# MIMXRT1021 register map
Vendor: nxp.com; File version: 1.0
CPU: CM7 r0p1, little endian, MPU, FPU, VTOR, 4 interrupt priority bits
Registers are 32-bit, read-write, reset 0x0 unless marked. A register's access mark holds for its fields unless they carry their own. Offsets are from the block's base; [hi:lo] are bit positions.

## IOMUXC (part 1 of 3)
Base 0x401F8000; register names take the prefix IOMUXC_
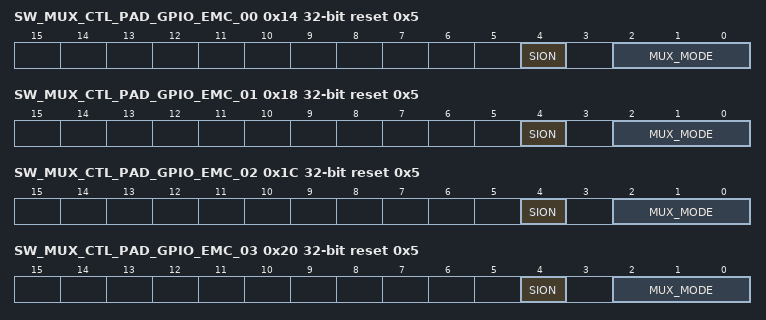
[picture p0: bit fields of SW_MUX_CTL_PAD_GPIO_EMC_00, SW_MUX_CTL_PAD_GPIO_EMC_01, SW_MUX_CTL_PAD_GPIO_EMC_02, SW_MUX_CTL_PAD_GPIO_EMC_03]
0x14 SW_MUX_CTL_PAD_GPIO_EMC_00 reset 0x5 — SW_MUX_CTL_PAD_GPIO_EMC_00 SW MUX Control Register
  [4] SION — Software Input On Field.
    0=DISABLED (Input Path is determined by functionality); 1=ENABLED (Force input path of pad GPIO_EMC_00)
  [2:0] MUX_MODE — MUX Mode Select Field.
    0=ALT0 (Select mux mode: ALT0 mux port: SEMC_DATA00 of instance: semc); 1=ALT1 (Select mux mode: ALT1 mux port: QTIMER2_TIMER0 of instance: qtimer2); 2=ALT2 (Select mux mode: ALT2 mux port: LPUART4_CTS_B of instance: lpuart4); 3=ALT3 (Select mux mode: ALT3 mux port: SPDIF_SR_CLK of instance: spdif); 4=ALT4 (Select mux mode: ALT4 mux port: LPSPI2_SCK of instance: lpspi2); 5=ALT5 (Select mux mode: ALT5 mux port: GPIO2_IO00 of instance: gpio2); 6=ALT6 (Select mux mode: ALT6 mux port: FLEXCAN1_TX of instance: flexcan1); 7=ALT7 (Select mux mode: ALT7 mux port: PIT_TRIGGER02 of instance: pit)
0x18 SW_MUX_CTL_PAD_GPIO_EMC_01 reset 0x5 — SW_MUX_CTL_PAD_GPIO_EMC_01 SW MUX Control Register
  [4] SION — Software Input On Field.
    0=DISABLED (Input Path is determined by functionality); 1=ENABLED (Force input path of pad GPIO_EMC_01)
  [2:0] MUX_MODE — MUX Mode Select Field.
    0=ALT0 (Select mux mode: ALT0 mux port: SEMC_DATA01 of instance: semc); 1=ALT1 (Select mux mode: ALT1 mux port: QTIMER2_TIMER1 of instance: qtimer2); 2=ALT2 (Select mux mode: ALT2 mux port: LPUART4_RTS_B of instance: lpuart4); 3=ALT3 (Select mux mode: ALT3 mux port: SPDIF_OUT of instance: spdif); 4=ALT4 (Select mux mode: ALT4 mux port: LPSPI2_PCS0 of instance: lpspi2); 5=ALT5 (Select mux mode: ALT5 mux port: GPIO2_IO01 of instance: gpio2); 6=ALT6 (Select mux mode: ALT6 mux port: FLEXCAN1_RX of instance: flexcan1); 7=ALT7 (Select mux mode: ALT7 mux port: PIT_TRIGGER03 of instance: pit)
0x1C SW_MUX_CTL_PAD_GPIO_EMC_02 reset 0x5 — SW_MUX_CTL_PAD_GPIO_EMC_02 SW MUX Control Register
  [4] SION — Software Input On Field.
    0=DISABLED (Input Path is determined by functionality); 1=ENABLED (Force input path of pad GPIO_EMC_02)
  [2:0] MUX_MODE — MUX Mode Select Field.
    0=ALT0 (Select mux mode: ALT0 mux port: SEMC_DATA02 of instance: semc); 1=ALT1 (Select mux mode: ALT1 mux port: QTIMER2_TIMER2 of instance: qtimer2); 2=ALT2 (Select mux mode: ALT2 mux port: LPUART4_TX of instance: lpuart4); 3=ALT3 (Select mux mode: ALT3 mux port: SPDIF_LOCK of instance: spdif); 4=ALT4 (Select mux mode: ALT4 mux port: LPSPI2_SDO of instance: lpspi2); 5=ALT5 (Select mux mode: ALT5 mux port: GPIO2_IO02 of instance: gpio2); 6=ALT6 (Select mux mode: ALT6 mux port: LPI2C1_SCL of instance: lpi2c1)
0x20 SW_MUX_CTL_PAD_GPIO_EMC_03 reset 0x5 — SW_MUX_CTL_PAD_GPIO_EMC_03 SW MUX Control Register
  [4] SION — Software Input On Field.
    0=DISABLED (Input Path is determined by functionality); 1=ENABLED (Force input path of pad GPIO_EMC_03)
  [2:0] MUX_MODE — MUX Mode Select Field.
    0=ALT0 (Select mux mode: ALT0 mux port: SEMC_DATA03 of instance: semc); 1=ALT1 (Select mux mode: ALT1 mux port: QTIMER2_TIMER3 of instance: qtimer2); 2=ALT2 (Select mux mode: ALT2 mux port: LPUART4_RX of instance: lpuart4); 3=ALT3 (Select mux mode: ALT3 mux port: SPDIF_EXT_CLK of instance: spdif); 4=ALT4 (Select mux mode: ALT4 mux port: LPSPI2_SDI of instance: lpspi2); 5=ALT5 (Select mux mode: ALT5 mux port: GPIO2_IO03 of instance: gpio2); 6=ALT6 (Select mux mode: ALT6 mux port: LPI2C1_SDA of instance: lpi2c1)
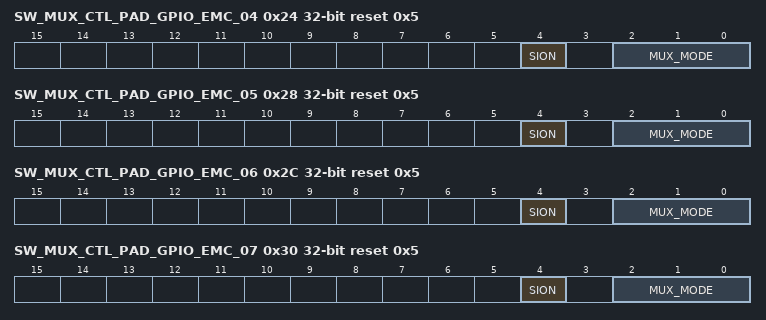
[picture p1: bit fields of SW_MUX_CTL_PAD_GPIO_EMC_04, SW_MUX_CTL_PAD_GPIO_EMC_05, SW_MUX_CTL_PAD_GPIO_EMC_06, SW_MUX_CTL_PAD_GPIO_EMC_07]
0x24 SW_MUX_CTL_PAD_GPIO_EMC_04 reset 0x5 — SW_MUX_CTL_PAD_GPIO_EMC_04 SW MUX Control Register
  [4] SION — Software Input On Field.
    0=DISABLED (Input Path is determined by functionality); 1=ENABLED (Force input path of pad GPIO_EMC_04)
  [2:0] MUX_MODE — MUX Mode Select Field.
    0=ALT0 (Select mux mode: ALT0 mux port: SEMC_DATA04 of instance: semc); 1=ALT1 (Select mux mode: ALT1 mux port: XBAR1_INOUT04 of instance: xbar1); 2=ALT2 (Select mux mode: ALT2 mux port: SPDIF_OUT of instance: spdif); 3=ALT3 (Select mux mode: ALT3 mux port: SAI2_TX_BCLK of instance: sai2); 4=ALT4 (Select mux mode: ALT4 mux port: FLEXIO1_FLEXIO16 of instance: flexio1); 5=ALT5 (Select mux mode: ALT5 mux port: GPIO2_IO04 of instance: gpio2)
0x28 SW_MUX_CTL_PAD_GPIO_EMC_05 reset 0x5 — SW_MUX_CTL_PAD_GPIO_EMC_05 SW MUX Control Register
  [4] SION — Software Input On Field.
    0=DISABLED (Input Path is determined by functionality); 1=ENABLED (Force input path of pad GPIO_EMC_05)
  [2:0] MUX_MODE — MUX Mode Select Field.
    0=ALT0 (Select mux mode: ALT0 mux port: SEMC_DATA05 of instance: semc); 1=ALT1 (Select mux mode: ALT1 mux port: XBAR1_INOUT05 of instance: xbar1); 2=ALT2 (Select mux mode: ALT2 mux port: SPDIF_IN of instance: spdif); 3=ALT3 (Select mux mode: ALT3 mux port: SAI2_TX_SYNC of instance: sai2); 4=ALT4 (Select mux mode: ALT4 mux port: FLEXIO1_FLEXIO17 of instance: flexio1); 5=ALT5 (Select mux mode: ALT5 mux port: GPIO2_IO05 of instance: gpio2)
0x2C SW_MUX_CTL_PAD_GPIO_EMC_06 reset 0x5 — SW_MUX_CTL_PAD_GPIO_EMC_06 SW MUX Control Register
  [4] SION — Software Input On Field.
    0=DISABLED (Input Path is determined by functionality); 1=ENABLED (Force input path of pad GPIO_EMC_06)
  [2:0] MUX_MODE — MUX Mode Select Field.
    0=ALT0 (Select mux mode: ALT0 mux port: SEMC_DATA06 of instance: semc); 1=ALT1 (Select mux mode: ALT1 mux port: XBAR1_INOUT06 of instance: xbar1); 2=ALT2 (Select mux mode: ALT2 mux port: LPUART3_TX of instance: lpuart3); 3=ALT3 (Select mux mode: ALT3 mux port: SAI2_TX_DATA of instance: sai2); 4=ALT4 (Select mux mode: ALT4 mux port: FLEXIO1_FLEXIO18 of instance: flexio1); 5=ALT5 (Select mux mode: ALT5 mux port: GPIO2_IO06 of instance: gpio2)
0x30 SW_MUX_CTL_PAD_GPIO_EMC_07 reset 0x5 — SW_MUX_CTL_PAD_GPIO_EMC_07 SW MUX Control Register
  [4] SION — Software Input On Field.
    0=DISABLED (Input Path is determined by functionality); 1=ENABLED (Force input path of pad GPIO_EMC_07)
  [2:0] MUX_MODE — MUX Mode Select Field.
    0=ALT0 (Select mux mode: ALT0 mux port: SEMC_DATA07 of instance: semc); 1=ALT1 (Select mux mode: ALT1 mux port: XBAR1_INOUT07 of instance: xbar1); 2=ALT2 (Select mux mode: ALT2 mux port: LPUART3_RX of instance: lpuart3); 3=ALT3 (Select mux mode: ALT3 mux port: SAI2_RX_SYNC of instance: sai2); 4=ALT4 (Select mux mode: ALT4 mux port: FLEXIO1_FLEXIO19 of instance: flexio1); 5=ALT5 (Select mux mode: ALT5 mux port: GPIO2_IO07 of instance: gpio2)
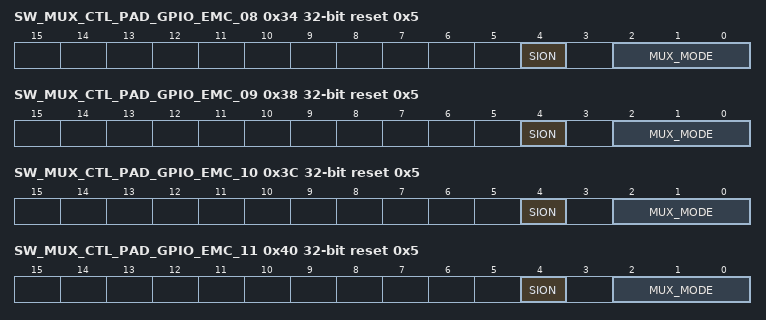
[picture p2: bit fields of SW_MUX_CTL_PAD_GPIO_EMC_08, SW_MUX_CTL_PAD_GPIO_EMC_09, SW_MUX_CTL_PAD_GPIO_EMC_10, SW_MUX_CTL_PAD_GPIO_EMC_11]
0x34 SW_MUX_CTL_PAD_GPIO_EMC_08 reset 0x5 — SW_MUX_CTL_PAD_GPIO_EMC_08 SW MUX Control Register
  [4] SION — Software Input On Field.
    0=DISABLED (Input Path is determined by functionality); 1=ENABLED (Force input path of pad GPIO_EMC_08)
  [2:0] MUX_MODE — MUX Mode Select Field.
    0=ALT0 (Select mux mode: ALT0 mux port: SEMC_DM00 of instance: semc); 1=ALT1 (Select mux mode: ALT1 mux port: XBAR1_INOUT08 of instance: xbar1); 2=ALT2 (Select mux mode: ALT2 mux port: FLEXCAN2_TX of instance: flexcan2); 3=ALT3 (Select mux mode: ALT3 mux port: SAI2_RX_DATA of instance: sai2); 4=ALT4 (Select mux mode: ALT4 mux port: FLEXIO1_FLEXIO20 of instance: flexio1); 5=ALT5 (Select mux mode: ALT5 mux port: GPIO2_IO08 of instance: gpio2)
0x38 SW_MUX_CTL_PAD_GPIO_EMC_09 reset 0x5 — SW_MUX_CTL_PAD_GPIO_EMC_09 SW MUX Control Register
  [4] SION — Software Input On Field.
    0=DISABLED (Input Path is determined by functionality); 1=ENABLED (Force input path of pad GPIO_EMC_09)
  [2:0] MUX_MODE — MUX Mode Select Field.
    0=ALT0 (Select mux mode: ALT0 mux port: SEMC_WE of instance: semc); 1=ALT1 (Select mux mode: ALT1 mux port: XBAR1_INOUT09 of instance: xbar1); 2=ALT2 (Select mux mode: ALT2 mux port: FLEXCAN2_RX of instance: flexcan2); 3=ALT3 (Select mux mode: ALT3 mux port: SAI2_RX_BCLK of instance: sai2); 4=ALT4 (Select mux mode: ALT4 mux port: FLEXIO1_FLEXIO21 of instance: flexio1); 5=ALT5 (Select mux mode: ALT5 mux port: GPIO2_IO09 of instance: gpio2)
0x3C SW_MUX_CTL_PAD_GPIO_EMC_10 reset 0x5 — SW_MUX_CTL_PAD_GPIO_EMC_10 SW MUX Control Register
  [4] SION — Software Input On Field.
    0=DISABLED (Input Path is determined by functionality); 1=ENABLED (Force input path of pad GPIO_EMC_10)
  [2:0] MUX_MODE — MUX Mode Select Field.
    0=ALT0 (Select mux mode: ALT0 mux port: SEMC_CAS of instance: semc); 1=ALT1 (Select mux mode: ALT1 mux port: XBAR1_INOUT10 of instance: xbar1); 2=ALT2 (Select mux mode: ALT2 mux port: LPI2C4_SDA of instance: lpi2c4); 3=ALT3 (Select mux mode: ALT3 mux port: SAI1_TX_SYNC of instance: sai1); 4=ALT4 (Select mux mode: ALT4 mux port: LPSPI2_SCK of instance: lpspi2); 5=ALT5 (Select mux mode: ALT5 mux port: GPIO2_IO10 of instance: gpio2); 6=ALT6 (Select mux mode: ALT6 mux port: FLEXPWM2_PWMX00 of instance: flexpwm2)
0x40 SW_MUX_CTL_PAD_GPIO_EMC_11 reset 0x5 — SW_MUX_CTL_PAD_GPIO_EMC_11 SW MUX Control Register
  [4] SION — Software Input On Field.
    0=DISABLED (Input Path is determined by functionality); 1=ENABLED (Force input path of pad GPIO_EMC_11)
  [2:0] MUX_MODE — MUX Mode Select Field.
    0=ALT0 (Select mux mode: ALT0 mux port: SEMC_RAS of instance: semc); 1=ALT1 (Select mux mode: ALT1 mux port: XBAR1_INOUT11 of instance: xbar1); 2=ALT2 (Select mux mode: ALT2 mux port: LPI2C4_SCL of instance: lpi2c4); 3=ALT3 (Select mux mode: ALT3 mux port: SAI1_TX_BCLK of instance: sai1); 4=ALT4 (Select mux mode: ALT4 mux port: LPSPI2_PCS0 of instance: lpspi2); 5=ALT5 (Select mux mode: ALT5 mux port: GPIO2_IO11 of instance: gpio2); 6=ALT6 (Select mux mode: ALT6 mux port: FLEXPWM2_PWMX01 of instance: flexpwm2)
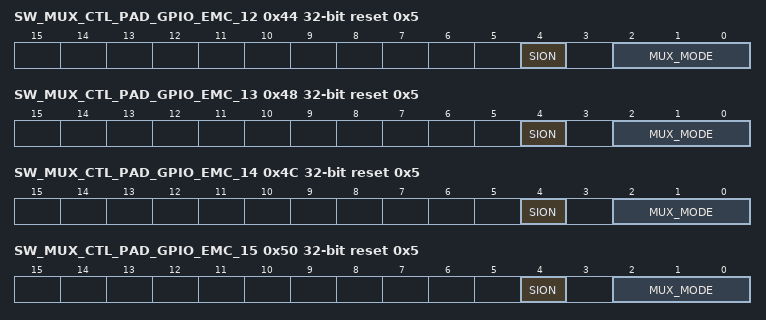
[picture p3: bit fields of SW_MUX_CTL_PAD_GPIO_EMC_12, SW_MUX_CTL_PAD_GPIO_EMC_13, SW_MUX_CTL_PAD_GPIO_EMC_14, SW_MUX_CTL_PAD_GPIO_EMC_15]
0x44 SW_MUX_CTL_PAD_GPIO_EMC_12 reset 0x5 — SW_MUX_CTL_PAD_GPIO_EMC_12 SW MUX Control Register
  [4] SION — Software Input On Field.
    0=DISABLED (Input Path is determined by functionality); 1=ENABLED (Force input path of pad GPIO_EMC_12)
  [2:0] MUX_MODE — MUX Mode Select Field.
    0=ALT0 (Select mux mode: ALT0 mux port: SEMC_CS0 of instance: semc); 1=ALT1 (Select mux mode: ALT1 mux port: XBAR1_INOUT12 of instance: xbar1); 2=ALT2 (Select mux mode: ALT2 mux port: LPUART6_TX of instance: lpuart6); 3=ALT3 (Select mux mode: ALT3 mux port: SAI1_TX_DATA00 of instance: sai1); 4=ALT4 (Select mux mode: ALT4 mux port: LPSPI2_SDO of instance: lpspi2); 5=ALT5 (Select mux mode: ALT5 mux port: GPIO2_IO12 of instance: gpio2); 6=ALT6 (Select mux mode: ALT6 mux port: FLEXPWM2_PWMX02 of instance: flexpwm2)
0x48 SW_MUX_CTL_PAD_GPIO_EMC_13 reset 0x5 — SW_MUX_CTL_PAD_GPIO_EMC_13 SW MUX Control Register
  [4] SION — Software Input On Field.
    0=DISABLED (Input Path is determined by functionality); 1=ENABLED (Force input path of pad GPIO_EMC_13)
  [2:0] MUX_MODE — MUX Mode Select Field.
    0=ALT0 (Select mux mode: ALT0 mux port: SEMC_BA0 of instance: semc); 1=ALT1 (Select mux mode: ALT1 mux port: XBAR1_INOUT13 of instance: xbar1); 2=ALT2 (Select mux mode: ALT2 mux port: LPUART6_RX of instance: lpuart6); 3=ALT3 (Select mux mode: ALT3 mux port: SAI1_RX_DATA00 of instance: sai1); 4=ALT4 (Select mux mode: ALT4 mux port: LPSPI2_SDI of instance: lpspi2); 5=ALT5 (Select mux mode: ALT5 mux port: GPIO2_IO13 of instance: gpio2); 6=ALT6 (Select mux mode: ALT6 mux port: FLEXPWM2_PWMX03 of instance: flexpwm2); 7=ALT7 (Select mux mode: ALT7 mux port: CCM_PMIC_RDY of instance: ccm)
0x4C SW_MUX_CTL_PAD_GPIO_EMC_14 reset 0x5 — SW_MUX_CTL_PAD_GPIO_EMC_14 SW MUX Control Register
  [4] SION — Software Input On Field.
    0=DISABLED (Input Path is determined by functionality); 1=ENABLED (Force input path of pad GPIO_EMC_14)
  [2:0] MUX_MODE — MUX Mode Select Field.
    0=ALT0 (Select mux mode: ALT0 mux port: SEMC_BA1 of instance: semc); 1=ALT1 (Select mux mode: ALT1 mux port: XBAR1_INOUT14 of instance: xbar1); 2=ALT2 (Select mux mode: ALT2 mux port: LPUART6_CTS_B of instance: lpuart6); 3=ALT3 (Select mux mode: ALT3 mux port: SAI1_RX_BCLK of instance: sai1); 4=ALT4 (Select mux mode: ALT4 mux port: LPSPI2_PCS1 of instance: lpspi2); 5=ALT5 (Select mux mode: ALT5 mux port: GPIO2_IO14 of instance: gpio2); 6=ALT6_flexcan1_TX (Select mux mode: ALT6 mux port: FLEXCAN1_TX of instance: flexcan1)
0x50 SW_MUX_CTL_PAD_GPIO_EMC_15 reset 0x5 — SW_MUX_CTL_PAD_GPIO_EMC_15 SW MUX Control Register
  [4] SION — Software Input On Field.
    0=DISABLED (Input Path is determined by functionality); 1=ENABLED (Force input path of pad GPIO_EMC_15)
  [2:0] MUX_MODE — MUX Mode Select Field.
    0=ALT0 (Select mux mode: ALT0 mux port: SEMC_ADDR10 of instance: semc); 1=ALT1 (Select mux mode: ALT1 mux port: XBAR1_INOUT15 of instance: xbar1); 2=ALT2 (Select mux mode: ALT2 mux port: LPUART6_RTS_B of instance: lpuart6); 3=ALT3 (Select mux mode: ALT3 mux port: SAI1_RX_SYNC of instance: sai1); 4=ALT4 (Select mux mode: ALT4 mux port: WDOG1_B of instance: wdog1); 5=ALT5 (Select mux mode: ALT5 mux port: GPIO2_IO15 of instance: gpio2); 6=ALT6 (Select mux mode: ALT6 mux port: FLEXCAN1_RX of instance: flexcan1)
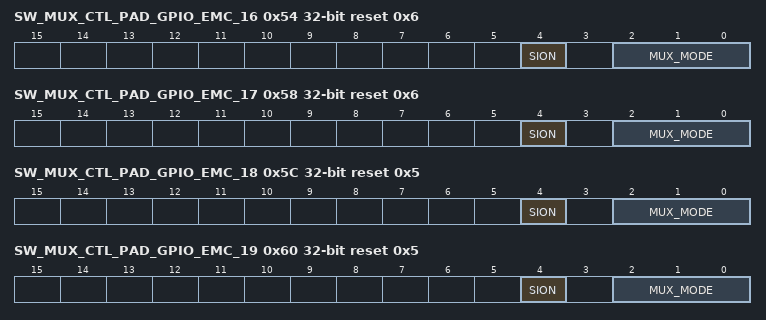
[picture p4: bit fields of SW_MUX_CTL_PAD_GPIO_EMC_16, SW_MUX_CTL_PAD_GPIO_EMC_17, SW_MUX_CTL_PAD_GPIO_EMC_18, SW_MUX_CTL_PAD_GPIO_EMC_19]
0x54 SW_MUX_CTL_PAD_GPIO_EMC_16 reset 0x6 — SW_MUX_CTL_PAD_GPIO_EMC_16 SW MUX Control Register
  [4] SION — Software Input On Field.
    0=DISABLED (Input Path is determined by functionality); 1=ENABLED (Force input path of pad GPIO_EMC_16)
  [2:0] MUX_MODE — MUX Mode Select Field.
    0=ALT0 (Select mux mode: ALT0 mux port: SEMC_ADDR00 of instance: semc); 2=ALT2 (Select mux mode: ALT2 mux port: MQS_RIGHT of instance: mqs); 3=ALT3 (Select mux mode: ALT3 mux port: SAI2_MCLK of instance: sai2); 5=ALT5 (Select mux mode: ALT5 mux port: GPIO2_IO16 of instance: gpio2); 6=ALT6 (Select mux mode: ALT6 mux port: SRC_BOOT_MODE00 of instance: src)
0x58 SW_MUX_CTL_PAD_GPIO_EMC_17 reset 0x6 — SW_MUX_CTL_PAD_GPIO_EMC_17 SW MUX Control Register
  [4] SION — Software Input On Field.
    0=DISABLED (Input Path is determined by functionality); 1=ENABLED (Force input path of pad GPIO_EMC_17)
  [2:0] MUX_MODE — MUX Mode Select Field.
    0=ALT0 (Select mux mode: ALT0 mux port: SEMC_ADDR01 of instance: semc); 2=ALT2 (Select mux mode: ALT2 mux port: MQS_LEFT of instance: mqs); 3=ALT3 (Select mux mode: ALT3 mux port: SAI3_MCLK of instance: sai3); 5=ALT5 (Select mux mode: ALT5 mux port: GPIO2_IO17 of instance: gpio2); 6=ALT6 (Select mux mode: ALT6 mux port: SRC_BOOT_MODE01 of instance: src)
0x5C SW_MUX_CTL_PAD_GPIO_EMC_18 reset 0x5 — SW_MUX_CTL_PAD_GPIO_EMC_18 SW MUX Control Register
  [4] SION — Software Input On Field.
    0=DISABLED (Input Path is determined by functionality); 1=ENABLED (Force input path of pad GPIO_EMC_18)
  [2:0] MUX_MODE — MUX Mode Select Field.
    0=ALT0 (Select mux mode: ALT0 mux port: SEMC_ADDR02 of instance: semc); 1=ALT1 (Select mux mode: ALT1 mux port: XBAR1_INOUT16 of instance: xbar1); 2=ALT2 (Select mux mode: ALT2 mux port: LPI2C2_SDA of instance: lpi2c2); 3=ALT3 (Select mux mode: ALT3 mux port: SAI1_RX_SYNC of instance: sai1); 4=ALT4 (Select mux mode: ALT4 mux port: FLEXIO1_FLEXIO22 of instance: flexio1); 5=ALT5 (Select mux mode: ALT5 mux port: GPIO2_IO18 of instance: gpio2); 6=ALT6 (Select mux mode: ALT6 mux port: SRC_BT_CFG00 of instance: src)
0x60 SW_MUX_CTL_PAD_GPIO_EMC_19 reset 0x5 — SW_MUX_CTL_PAD_GPIO_EMC_19 SW MUX Control Register
  [4] SION — Software Input On Field.
    0=DISABLED (Input Path is determined by functionality); 1=ENABLED (Force input path of pad GPIO_EMC_19)
  [2:0] MUX_MODE — MUX Mode Select Field.
    0=ALT0 (Select mux mode: ALT0 mux port: SEMC_ADDR03 of instance: semc); 1=ALT1 (Select mux mode: ALT1 mux port: XBAR1_INOUT17 of instance: xbar1); 2=ALT2 (Select mux mode: ALT2 mux port: LPI2C2_SCL of instance: lpi2c2); 3=ALT3 (Select mux mode: ALT3 mux port: SAI1_RX_BCLK of instance: sai1); 4=ALT4 (Select mux mode: ALT4 mux port: FLEXIO1_FLEXIO23 of instance: flexio1); 5=ALT5 (Select mux mode: ALT5 mux port: GPIO2_IO19 of instance: gpio2); 6=ALT6 (Select mux mode: ALT6 mux port: SRC_BT_CFG01 of instance: src)
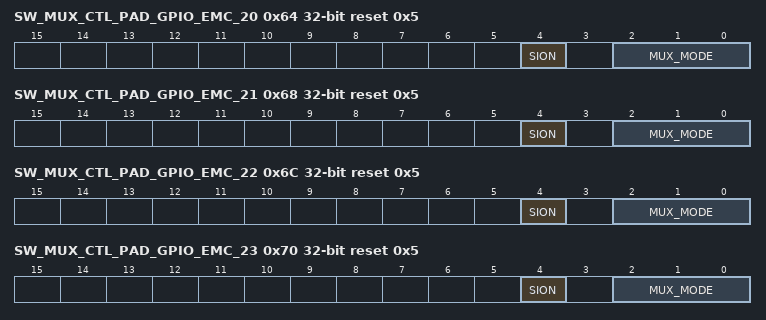
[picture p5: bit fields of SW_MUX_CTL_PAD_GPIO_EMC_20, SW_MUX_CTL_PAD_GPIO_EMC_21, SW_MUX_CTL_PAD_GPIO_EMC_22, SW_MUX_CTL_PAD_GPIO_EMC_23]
0x64 SW_MUX_CTL_PAD_GPIO_EMC_20 reset 0x5 — SW_MUX_CTL_PAD_GPIO_EMC_20 SW MUX Control Register
  [4] SION — Software Input On Field.
    0=DISABLED (Input Path is determined by functionality); 1=ENABLED (Force input path of pad GPIO_EMC_20)
  [2:0] MUX_MODE — MUX Mode Select Field.
    0=ALT0 (Select mux mode: ALT0 mux port: SEMC_ADDR04 of instance: semc); 1=ALT1 (Select mux mode: ALT1 mux port: FLEXPWM1_PWMA03 of instance: flexpwm1); 2=ALT2 (Select mux mode: ALT2 mux port: LPUART2_CTS_B of instance: lpuart2); 3=ALT3 (Select mux mode: ALT3 mux port: SAI1_MCLK of instance: sai1); 4=ALT4 (Select mux mode: ALT4 mux port: FLEXIO1_FLEXIO24 of instance: flexio1); 5=ALT5 (Select mux mode: ALT5 mux port: GPIO2_IO20 of instance: gpio2); 6=ALT6 (Select mux mode: ALT6 mux port: SRC_BT_CFG02 of instance: src)
0x68 SW_MUX_CTL_PAD_GPIO_EMC_21 reset 0x5 — SW_MUX_CTL_PAD_GPIO_EMC_21 SW MUX Control Register
  [4] SION — Software Input On Field.
    0=DISABLED (Input Path is determined by functionality); 1=ENABLED (Force input path of pad GPIO_EMC_21)
  [2:0] MUX_MODE — MUX Mode Select Field.
    0=ALT0 (Select mux mode: ALT0 mux port: SEMC_ADDR05 of instance: semc); 1=ALT1 (Select mux mode: ALT1 mux port: FLEXPWM1_PWMB03 of instance: flexpwm1); 2=ALT2 (Select mux mode: ALT2 mux port: LPUART2_RTS_B of instance: lpuart2); 3=ALT3 (Select mux mode: ALT3 mux port: SAI1_RX_DATA00 of instance: sai1); 4=ALT4 (Select mux mode: ALT4 mux port: FLEXIO1_FLEXIO25 of instance: flexio1); 5=ALT5 (Select mux mode: ALT5 mux port: GPIO2_IO21 of instance: gpio2); 6=ALT6 (Select mux mode: ALT6 mux port: SRC_BT_CFG03 of instance: src)
0x6C SW_MUX_CTL_PAD_GPIO_EMC_22 reset 0x5 — SW_MUX_CTL_PAD_GPIO_EMC_22 SW MUX Control Register
  [4] SION — Software Input On Field.
    0=DISABLED (Input Path is determined by functionality); 1=ENABLED (Force input path of pad GPIO_EMC_22)
  [2:0] MUX_MODE — MUX Mode Select Field.
    0=ALT0 (Select mux mode: ALT0 mux port: SEMC_ADDR06 of instance: semc); 1=ALT1 (Select mux mode: ALT1 mux port: FLEXPWM1_PWMA02 of instance: flexpwm1); 2=ALT2 (Select mux mode: ALT2 mux port: LPUART2_TX of instance: lpuart2); 3=ALT3 (Select mux mode: ALT3 mux port: SAI1_TX_DATA03 of instance: sai1); 4=ALT4 (Select mux mode: ALT4 mux port: FLEXIO1_FLEXIO26 of instance: flexio1); 5=ALT5 (Select mux mode: ALT5 mux port: GPIO2_IO22 of instance: gpio2); 6=ALT6 (Select mux mode: ALT6 mux port: SRC_BT_CFG04 of instance: src)
0x70 SW_MUX_CTL_PAD_GPIO_EMC_23 reset 0x5 — SW_MUX_CTL_PAD_GPIO_EMC_23 SW MUX Control Register
  [4] SION — Software Input On Field.
    0=DISABLED (Input Path is determined by functionality); 1=ENABLED (Force input path of pad GPIO_EMC_23)
  [2:0] MUX_MODE — MUX Mode Select Field.
    0=ALT0 (Select mux mode: ALT0 mux port: SEMC_ADDR07 of instance: semc); 1=ALT1 (Select mux mode: ALT1 mux port: FLEXPWM1_PWMB02 of instance: flexpwm1); 2=ALT2 (Select mux mode: ALT2 mux port: LPUART2_RX of instance: lpuart2); 3=ALT3 (Select mux mode: ALT3 mux port: SAI1_TX_DATA02 of instance: sai1); 4=ALT4 (Select mux mode: ALT4 mux port: FLEXIO1_FLEXIO27 of instance: flexio1); 5=ALT5 (Select mux mode: ALT5 mux port: GPIO2_IO23 of instance: gpio2); 6=ALT6 (Select mux mode: ALT6 mux port: SRC_BT_CFG05 of instance: src)
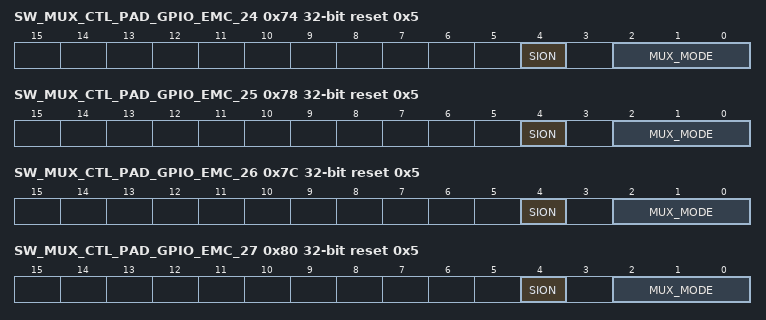
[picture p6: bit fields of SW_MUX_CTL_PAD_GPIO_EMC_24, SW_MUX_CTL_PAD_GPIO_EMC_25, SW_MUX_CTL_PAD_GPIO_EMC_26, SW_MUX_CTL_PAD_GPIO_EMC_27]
0x74 SW_MUX_CTL_PAD_GPIO_EMC_24 reset 0x5 — SW_MUX_CTL_PAD_GPIO_EMC_24 SW MUX Control Register
  [4] SION — Software Input On Field.
    0=DISABLED (Input Path is determined by functionality); 1=ENABLED (Force input path of pad GPIO_EMC_24)
  [2:0] MUX_MODE — MUX Mode Select Field.
    0=ALT0 (Select mux mode: ALT0 mux port: SEMC_ADDR08 of instance: semc); 1=ALT1 (Select mux mode: ALT1 mux port: FLEXPWM1_PWMA01 of instance: flexpwm1); 2=ALT2 (Select mux mode: ALT2 mux port: LPUART8_CTS_B of instance: lpuart8); 3=ALT3 (Select mux mode: ALT3 mux port: SAI1_TX_DATA01 of instance: sai1); 4=ALT4 (Select mux mode: ALT4 mux port: FLEXIO1_FLEXIO28 of instance: flexio1); 5=ALT5 (Select mux mode: ALT5 mux port: GPIO2_IO24 of instance: gpio2); 6=ALT6 (Select mux mode: ALT6 mux port: SRC_BT_CFG06 of instance: src)
0x78 SW_MUX_CTL_PAD_GPIO_EMC_25 reset 0x5 — SW_MUX_CTL_PAD_GPIO_EMC_25 SW MUX Control Register
  [4] SION — Software Input On Field.
    0=DISABLED (Input Path is determined by functionality); 1=ENABLED (Force input path of pad GPIO_EMC_25)
  [2:0] MUX_MODE — MUX Mode Select Field.
    0=ALT0 (Select mux mode: ALT0 mux port: SEMC_ADDR09 of instance: semc); 1=ALT1 (Select mux mode: ALT1 mux port: FLEXPWM1_PWMB01 of instance: flexpwm1); 2=ALT2 (Select mux mode: ALT2 mux port: LPUART8_RTS_B of instance: lpuart8); 3=ALT3 (Select mux mode: ALT3 mux port: SAI1_TX_DATA00 of instance: sai1); 4=ALT4 (Select mux mode: ALT4 mux port: FLEXIO1_FLEXIO29 of instance: flexio1); 5=ALT5 (Select mux mode: ALT5 mux port: GPIO2_IO25 of instance: gpio2); 6=ALT6 (Select mux mode: ALT6 mux port: SRC_BT_CFG07 of instance: src)
0x7C SW_MUX_CTL_PAD_GPIO_EMC_26 reset 0x5 — SW_MUX_CTL_PAD_GPIO_EMC_26 SW MUX Control Register
  [4] SION — Software Input On Field.
    0=DISABLED (Input Path is determined by functionality); 1=ENABLED (Force input path of pad GPIO_EMC_26)
  [2:0] MUX_MODE — MUX Mode Select Field.
    0=ALT0 (Select mux mode: ALT0 mux port: SEMC_ADDR11 of instance: semc); 1=ALT1 (Select mux mode: ALT1 mux port: FLEXPWM1_PWMA00 of instance: flexpwm1); 2=ALT2 (Select mux mode: ALT2 mux port: LPUART8_TX of instance: lpuart8); 3=ALT3 (Select mux mode: ALT3 mux port: SAI1_TX_BCLK of instance: sai1); 4=ALT4 (Select mux mode: ALT4 mux port: FLEXIO1_FLEXIO30 of instance: flexio1); 5=ALT5 (Select mux mode: ALT5 mux port: GPIO2_IO26 of instance: gpio2); 6=ALT6 (Select mux mode: ALT6 mux port: SRC_BT_CFG08 of instance: src)
0x80 SW_MUX_CTL_PAD_GPIO_EMC_27 reset 0x5 — SW_MUX_CTL_PAD_GPIO_EMC_27 SW MUX Control Register
  [4] SION — Software Input On Field.
    0=DISABLED (Input Path is determined by functionality); 1=ENABLED (Force input path of pad GPIO_EMC_27)
  [2:0] MUX_MODE — MUX Mode Select Field.
    0=ALT0 (Select mux mode: ALT0 mux port: SEMC_ADDR12 of instance: semc); 1=ALT1 (Select mux mode: ALT1 mux port: FLEXPWM1_PWMB00 of instance: flexpwm1); 2=ALT2 (Select mux mode: ALT2 mux port: LPUART8_RX of instance: lpuart8); 3=ALT3 (Select mux mode: ALT3 mux port: SAI1_TX_SYNC of instance: sai1); 4=ALT4 (Select mux mode: ALT4 mux port: FLEXIO1_FLEXIO31 of instance: flexio1); 5=ALT5 (Select mux mode: ALT5 mux port: GPIO2_IO27 of instance: gpio2); 6=ALT6 (Select mux mode: ALT6 mux port: SRC_BT_CFG09 of instance: src)
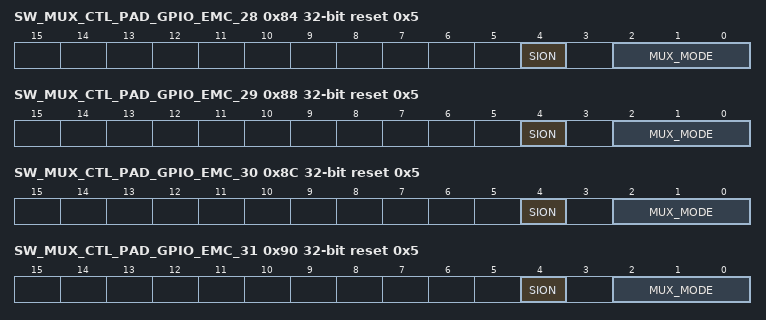
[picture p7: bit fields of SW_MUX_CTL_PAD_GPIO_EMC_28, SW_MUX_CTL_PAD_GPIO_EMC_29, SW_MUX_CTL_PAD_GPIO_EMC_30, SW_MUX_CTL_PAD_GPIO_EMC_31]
0x84 SW_MUX_CTL_PAD_GPIO_EMC_28 reset 0x5 — SW_MUX_CTL_PAD_GPIO_EMC_28 SW MUX Control Register
  [4] SION — Software Input On Field.
    0=DISABLED (Input Path is determined by functionality); 1=ENABLED (Force input path of pad GPIO_EMC_28)
  [2:0] MUX_MODE — MUX Mode Select Field.
    0=ALT0 (Select mux mode: ALT0 mux port: SEMC_DQS of instance: semc); 1=ALT1 (Select mux mode: ALT1 mux port: FLEXPWM2_PWMA03 of instance: flexpwm2); 2=ALT2 (Select mux mode: ALT2 mux port: XBAR1_INOUT18 of instance: xbar1); 3=ALT3 (Select mux mode: ALT3 mux port: SAI3_MCLK of instance: sai3); 4=ALT4 (Select mux mode: ALT4 mux port: EWM_OUT_B of instance: ewm); 5=ALT5 (Select mux mode: ALT5 mux port: GPIO2_IO28 of instance: gpio2); 6=ALT6 (Select mux mode: ALT6 mux port: GPT2_CAPTURE2 of instance: gpt2); 7=ALT7 (Select mux mode: ALT7 mux port: FLEXPWM1_PWMX00 of instance: flexpwm1)
0x88 SW_MUX_CTL_PAD_GPIO_EMC_29 reset 0x5 — SW_MUX_CTL_PAD_GPIO_EMC_29 SW MUX Control Register
  [4] SION — Software Input On Field.
    0=DISABLED (Input Path is determined by functionality); 1=ENABLED (Force input path of pad GPIO_EMC_29)
  [2:0] MUX_MODE — MUX Mode Select Field.
    0=ALT0 (Select mux mode: ALT0 mux port: SEMC_CKE of instance: semc); 1=ALT1 (Select mux mode: ALT1 mux port: FLEXPWM2_PWMB03 of instance: flexpwm2); 2=ALT2 (Select mux mode: ALT2 mux port: XBAR1_INOUT19 of instance: xbar1); 3=ALT3 (Select mux mode: ALT3 mux port: SAI3_RX_BCLK of instance: sai3); 4=ALT4 (Select mux mode: ALT4 mux port: WDOG2_RST_B_DEB of instance: wdog2); 5=ALT5 (Select mux mode: ALT5 mux port: GPIO2_IO29 of instance: gpio2); 6=ALT6 (Select mux mode: ALT6 mux port: GPT2_COMPARE2 of instance: gpt2); 7=ALT7 (Select mux mode: ALT7 mux port: FLEXPWM1_PWMX01 of instance: flexpwm1)
0x8C SW_MUX_CTL_PAD_GPIO_EMC_30 reset 0x5 — SW_MUX_CTL_PAD_GPIO_EMC_30 SW MUX Control Register
  [4] SION — Software Input On Field.
    0=DISABLED (Input Path is determined by functionality); 1=ENABLED (Force input path of pad GPIO_EMC_30)
  [2:0] MUX_MODE — MUX Mode Select Field.
    0=ALT0 (Select mux mode: ALT0 mux port: SEMC_CLK of instance: semc); 1=ALT1 (Select mux mode: ALT1 mux port: FLEXPWM2_PWMA02 of instance: flexpwm2); 2=ALT2 (Select mux mode: ALT2 mux port: LPUART4_CTS_B of instance: lpuart4); 3=ALT3 (Select mux mode: ALT3 mux port: SAI3_RX_SYNC of instance: sai3); 4=ALT4 (Select mux mode: ALT4 mux port: WDOG1_RST_B_DEB of instance: wdog1); 5=ALT5 (Select mux mode: ALT5 mux port: GPIO2_IO30 of instance: gpio2); 6=ALT6 (Select mux mode: ALT6 mux port: GPT2_COMPARE3 of instance: gpt2); 7=ALT7 (Select mux mode: ALT7 mux port: FLEXPWM1_PWMX02 of instance: flexpwm1)
0x90 SW_MUX_CTL_PAD_GPIO_EMC_31 reset 0x5 — SW_MUX_CTL_PAD_GPIO_EMC_31 SW MUX Control Register
  [4] SION — Software Input On Field.
    0=DISABLED (Input Path is determined by functionality); 1=ENABLED (Force input path of pad GPIO_EMC_31)
  [2:0] MUX_MODE — MUX Mode Select Field.
    0=ALT0 (Select mux mode: ALT0 mux port: SEMC_DM01 of instance: semc); 1=ALT1 (Select mux mode: ALT1 mux port: FLEXPWM2_PWMB02 of instance: flexpwm2); 2=ALT2 (Select mux mode: ALT2 mux port: LPUART4_RTS_B of instance: lpuart4); 3=ALT3 (Select mux mode: ALT3 mux port: SAI3_RX_DATA of instance: sai3); 4=ALT4 (Select mux mode: ALT4 mux port: WDOG2_B of instance: wdog2); 5=ALT5 (Select mux mode: ALT5 mux port: GPIO2_IO31 of instance: gpio2); 6=ALT6 (Select mux mode: ALT6 mux port: GPT2_CLK of instance: gpt2); 7=ALT7 (Select mux mode: ALT7 mux port: FLEXPWM1_PWMX03 of instance: flexpwm1)
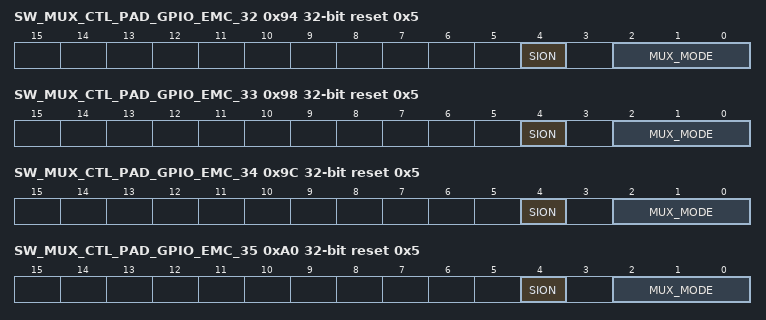
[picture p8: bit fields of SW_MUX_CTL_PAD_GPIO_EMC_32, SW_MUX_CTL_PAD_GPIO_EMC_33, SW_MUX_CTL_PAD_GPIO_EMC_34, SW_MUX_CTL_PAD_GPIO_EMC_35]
0x94 SW_MUX_CTL_PAD_GPIO_EMC_32 reset 0x5 — SW_MUX_CTL_PAD_GPIO_EMC_32 SW MUX Control Register
  [4] SION — Software Input On Field.
    0=DISABLED (Input Path is determined by functionality); 1=ENABLED (Force input path of pad GPIO_EMC_32)
  [2:0] MUX_MODE — MUX Mode Select Field.
    0=ALT0 (Select mux mode: ALT0 mux port: SEMC_DATA08 of instance: semc); 1=ALT1 (Select mux mode: ALT1 mux port: QTIMER1_TIMER0 of instance: qtimer1); 2=ALT2 (Select mux mode: ALT2 mux port: LPUART4_TX of instance: lpuart4); 3=ALT3 (Select mux mode: ALT3 mux port: SAI3_TX_DATA of instance: sai3); 4=ALT4 (Select mux mode: ALT4 mux port: LPSPI4_SCK of instance: lpspi4); 5=ALT5 (Select mux mode: ALT5 mux port: GPIO3_IO00 of instance: gpio3); 7=ALT7 (Select mux mode: ALT7 mux port: REF_24M_OUT of instance: anatop)
0x98 SW_MUX_CTL_PAD_GPIO_EMC_33 reset 0x5 — SW_MUX_CTL_PAD_GPIO_EMC_33 SW MUX Control Register
  [4] SION — Software Input On Field.
    0=DISABLED (Input Path is determined by functionality); 1=ENABLED (Force input path of pad GPIO_EMC_33)
  [2:0] MUX_MODE — MUX Mode Select Field.
    0=ALT0 (Select mux mode: ALT0 mux port: SEMC_DATA09 of instance: semc); 1=ALT1 (Select mux mode: ALT1 mux port: QTIMER1_TIMER1 of instance: qtimer1); 2=ALT2 (Select mux mode: ALT2 mux port: LPUART4_RX of instance: lpuart4); 3=ALT3 (Select mux mode: ALT3 mux port: SAI3_TX_BCLK of instance: sai3); 4=ALT4 (Select mux mode: ALT4 mux port: LPSPI4_PCS0 of instance: lpspi4); 5=ALT5 (Select mux mode: ALT5 mux port: GPIO3_IO01 of instance: gpio3)
0x9C SW_MUX_CTL_PAD_GPIO_EMC_34 reset 0x5 — SW_MUX_CTL_PAD_GPIO_EMC_34 SW MUX Control Register
  [4] SION — Software Input On Field.
    0=DISABLED (Input Path is determined by functionality); 1=ENABLED (Force input path of pad GPIO_EMC_34)
  [2:0] MUX_MODE — MUX Mode Select Field.
    0=ALT0 (Select mux mode: ALT0 mux port: SEMC_DATA10 of instance: semc); 1=ALT1 (Select mux mode: ALT1 mux port: QTIMER1_TIMER2 of instance: qtimer1); 2=ALT2 (Select mux mode: ALT2 mux port: LPUART7_TX of instance: lpuart7); 3=ALT3 (Select mux mode: ALT3 mux port: SAI3_TX_SYNC of instance: sai3); 4=ALT4 (Select mux mode: ALT4 mux port: LPSPI4_SDO of instance: lpspi4); 5=ALT5 (Select mux mode: ALT5 mux port: GPIO3_IO02 of instance: gpio3); 6=ALT6 (Select mux mode: ALT6 mux port: ENET_CRS of instance: enet)
0xA0 SW_MUX_CTL_PAD_GPIO_EMC_35 reset 0x5 — SW_MUX_CTL_PAD_GPIO_EMC_35 SW MUX Control Register
  [4] SION — Software Input On Field.
    0=DISABLED (Input Path is determined by functionality); 1=ENABLED (Force input path of pad GPIO_EMC_35)
  [2:0] MUX_MODE — MUX Mode Select Field.
    0=ALT0 (Select mux mode: ALT0 mux port: SEMC_DATA11 of instance: semc); 1=ALT1 (Select mux mode: ALT1 mux port: QTIMER1_TIMER3 of instance: qtimer1); 2=ALT2 (Select mux mode: ALT2 mux port: LPUART7_RX of instance: lpuart7); 3=ALT3 (Select mux mode: ALT3 mux port: USDHC2_WP of instance: usdhc2); 4=ALT4 (Select mux mode: ALT4 mux port: LPSPI4_SDI of instance: lpspi4); 5=ALT5 (Select mux mode: ALT5 mux port: GPIO3_IO03 of instance: gpio3); 6=ALT6 (Select mux mode: ALT6 mux port: ENET_COL of instance: enet)
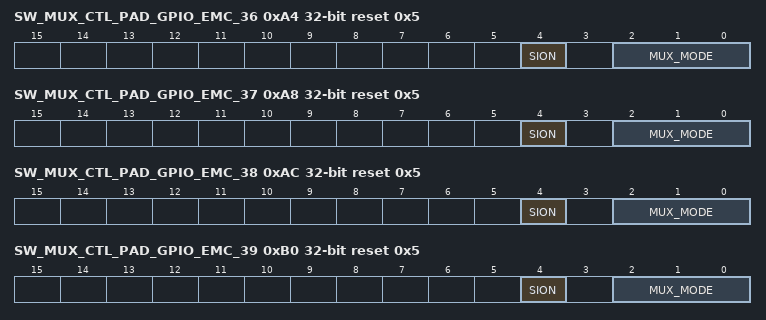
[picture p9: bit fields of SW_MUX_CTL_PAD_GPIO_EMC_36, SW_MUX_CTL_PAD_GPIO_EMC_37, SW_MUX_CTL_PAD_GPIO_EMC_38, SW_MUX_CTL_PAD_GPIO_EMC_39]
0xA4 SW_MUX_CTL_PAD_GPIO_EMC_36 reset 0x5 — SW_MUX_CTL_PAD_GPIO_EMC_36 SW MUX Control Register
  [4] SION — Software Input On Field.
    0=DISABLED (Input Path is determined by functionality); 1=ENABLED (Force input path of pad GPIO_EMC_36)
  [2:0] MUX_MODE — MUX Mode Select Field.
    0=ALT0 (Select mux mode: ALT0 mux port: SEMC_DATA12 of instance: semc); 1=ALT1 (Select mux mode: ALT1 mux port: FLEXPWM2_PWMA01 of instance: flexpwm2); 2=ALT2 (Select mux mode: ALT2 mux port: LPUART5_CTS_B of instance: lpuart5); 3=ALT3 (Select mux mode: ALT3 mux port: CCM_PMIC_RDY of instance: ccm); 4=ALT4 (Select mux mode: ALT4 mux port: LPSPI4_PCS1 of instance: lpspi4); 5=ALT5 (Select mux mode: ALT5 mux port: GPIO3_IO04 of instance: gpio3); 6=ALT6 (Select mux mode: ALT6 mux port: ENET_RX_CLK of instance: enet); 7=ALT7 (Select mux mode: ALT7 mux port: USDHC1_WP of instance: usdhc1)
0xA8 SW_MUX_CTL_PAD_GPIO_EMC_37 reset 0x5 — SW_MUX_CTL_PAD_GPIO_EMC_37 SW MUX Control Register
  [4] SION — Software Input On Field.
    0=DISABLED (Input Path is determined by functionality); 1=ENABLED (Force input path of pad GPIO_EMC_37)
  [2:0] MUX_MODE — MUX Mode Select Field.
    0=ALT0 (Select mux mode: ALT0 mux port: SEMC_DATA13 of instance: semc); 1=ALT1 (Select mux mode: ALT1 mux port: FLEXPWM2_PWMB01 of instance: flexpwm2); 2=ALT2 (Select mux mode: ALT2 mux port: LPUART5_RTS_B of instance: lpuart5); 3=ALT3 (Select mux mode: ALT3 mux port: MQS_RIGHT of instance: mqs); 4=ALT4 (Select mux mode: ALT4 mux port: LPSPI4_PCS2 of instance: lpspi4); 5=ALT5 (Select mux mode: ALT5 mux port: GPIO3_IO05 of instance: gpio3); 6=ALT6 (Select mux mode: ALT6 mux port: ENET_RDATA03 of instance: enet); 7=ALT7 (Select mux mode: ALT7 mux port: USDHC1_VSELECT of instance: usdhc1)
0xAC SW_MUX_CTL_PAD_GPIO_EMC_38 reset 0x5 — SW_MUX_CTL_PAD_GPIO_EMC_38 SW MUX Control Register
  [4] SION — Software Input On Field.
    0=DISABLED (Input Path is determined by functionality); 1=ENABLED (Force input path of pad GPIO_EMC_38)
  [2:0] MUX_MODE — MUX Mode Select Field.
    0=ALT0 (Select mux mode: ALT0 mux port: SEMC_DATA14 of instance: semc); 1=ALT1 (Select mux mode: ALT1 mux port: FLEXPWM2_PWMA00 of instance: flexpwm2); 2=ALT2 (Select mux mode: ALT2 mux port: LPUART5_TX of instance: lpuart5); 3=ALT3 (Select mux mode: ALT3 mux port: MQS_LEFT of instance: mqs); 4=ALT4 (Select mux mode: ALT4 mux port: LPSPI4_PCS3 of instance: lpspi4); 5=ALT5 (Select mux mode: ALT5 mux port: GPIO3_IO06 of instance: gpio3); 6=ALT6 (Select mux mode: ALT6 mux port: ENET_RDATA02 of instance: enet); 7=ALT7 (Select mux mode: ALT7 mux port: USDHC1_CD_B of instance: usdhc1)
0xB0 SW_MUX_CTL_PAD_GPIO_EMC_39 reset 0x5 — SW_MUX_CTL_PAD_GPIO_EMC_39 SW MUX Control Register
  [4] SION — Software Input On Field.
    0=DISABLED (Input Path is determined by functionality); 1=ENABLED (Force input path of pad GPIO_EMC_39)
  [2:0] MUX_MODE — MUX Mode Select Field.
    0=ALT0 (Select mux mode: ALT0 mux port: SEMC_DATA15 of instance: semc); 1=ALT1 (Select mux mode: ALT1 mux port: FLEXPWM2_PWMB00 of instance: flexpwm2); 2=ALT2 (Select mux mode: ALT2 mux port: LPUART5_RX of instance: lpuart5); 3=ALT3 (Select mux mode: ALT3 mux port: USB_OTG1_OC of instance: usb); 4=ALT4 (Select mux mode: ALT4 mux port: WDOG1_B of instance: wdog1); 5=ALT5 (Select mux mode: ALT5 mux port: GPIO3_IO07 of instance: gpio3); 6=ALT6 (Select mux mode: ALT6 mux port: ENET_TX_ER of instance: enet); 7=ALT7 (Select mux mode: ALT7 mux port: GPT1_CLK of instance: gpt1)
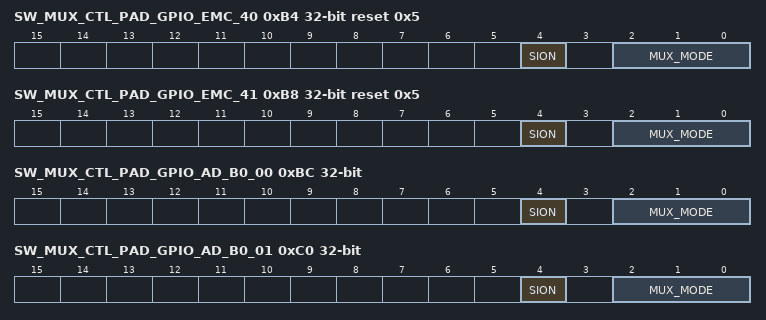
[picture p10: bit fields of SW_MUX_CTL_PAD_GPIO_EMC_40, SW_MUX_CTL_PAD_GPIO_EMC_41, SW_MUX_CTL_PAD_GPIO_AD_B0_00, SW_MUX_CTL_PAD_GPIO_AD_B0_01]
0xB4 SW_MUX_CTL_PAD_GPIO_EMC_40 reset 0x5 — SW_MUX_CTL_PAD_GPIO_EMC_40 SW MUX Control Register
  [4] SION — Software Input On Field.
    0=DISABLED (Input Path is determined by functionality); 1=ENABLED (Force input path of pad GPIO_EMC_40)
  [2:0] MUX_MODE — MUX Mode Select Field.
    0=ALT0 (Select mux mode: ALT0 mux port: SEMC_CSX00 of instance: semc); 1=ALT1 (Select mux mode: ALT1 mux port: XBAR1_INOUT18 of instance: xbar1); 2=ALT2 (Select mux mode: ALT2 mux port: SPDIF_OUT of instance: spdif); 3=ALT3 (Select mux mode: ALT3 mux port: USB_OTG1_ID of instance: anatop); 4=ALT4 (Select mux mode: ALT4 mux port: ENET_MDIO of instance: enet); 5=ALT5 (Select mux mode: ALT5 mux port: GPIO3_IO08 of instance: gpio3); 6=ALT6 (Select mux mode: ALT6 mux port: ENET_TDATA03 of instance: enet); 7=ALT7 (Select mux mode: ALT7 mux port: GPT1_COMPARE3 of instance: gpt1)
0xB8 SW_MUX_CTL_PAD_GPIO_EMC_41 reset 0x5 — SW_MUX_CTL_PAD_GPIO_EMC_41 SW MUX Control Register
  [4] SION — Software Input On Field.
    0=DISABLED (Input Path is determined by functionality); 1=ENABLED (Force input path of pad GPIO_EMC_41)
  [2:0] MUX_MODE — MUX Mode Select Field.
    0=ALT0 (Select mux mode: ALT0 mux port: SEMC_READY of instance: semc); 1=ALT1 (Select mux mode: ALT1 mux port: XBAR1_INOUT19 of instance: xbar1); 2=ALT2 (Select mux mode: ALT2 mux port: SPDIF_IN of instance: spdif); 3=ALT3 (Select mux mode: ALT3 mux port: USB_OTG1_PWR of instance: usb); 4=ALT4 (Select mux mode: ALT4 mux port: ENET_MDC of instance: enet); 5=ALT5 (Select mux mode: ALT5 mux port: GPIO3_IO09 of instance: gpio3); 6=ALT6 (Select mux mode: ALT6 mux port: ENET_TDATA02 of instance: enet); 7=ALT7 (Select mux mode: ALT7 mux port: GPT1_COMPARE2 of instance: gpt1)
0xBC SW_MUX_CTL_PAD_GPIO_AD_B0_00 — SW_MUX_CTL_PAD_GPIO_AD_B0_00 SW MUX Control Register
  [4] SION — Software Input On Field.
    0=DISABLED (Input Path is determined by functionality); 1=ENABLED (Force input path of pad GPIO_AD_B0_00)
  [2:0] MUX_MODE — MUX Mode Select Field.
    0=ALT0 (Select mux mode: ALT0 mux port: JTAG_TMS of instance: jtag_mux); 5=ALT5 (Select mux mode: ALT5 mux port: GPIO1_IO00 of instance: gpio1); 7=ALT7 (Select mux mode: ALT7 mux port: GPT1_COMPARE1 of instance: gpt1)
0xC0 SW_MUX_CTL_PAD_GPIO_AD_B0_01 — SW_MUX_CTL_PAD_GPIO_AD_B0_01 SW MUX Control Register
  [4] SION — Software Input On Field.
    0=DISABLED (Input Path is determined by functionality); 1=ENABLED (Force input path of pad GPIO_AD_B0_01)
  [2:0] MUX_MODE — MUX Mode Select Field.
    0=ALT0 (Select mux mode: ALT0 mux port: JTAG_TCK of instance: jtag_mux); 5=ALT5 (Select mux mode: ALT5 mux port: GPIO1_IO01 of instance: gpio1); 7=ALT7 (Select mux mode: ALT7 mux port: GPT1_CAPTURE2 of instance: gpt1)
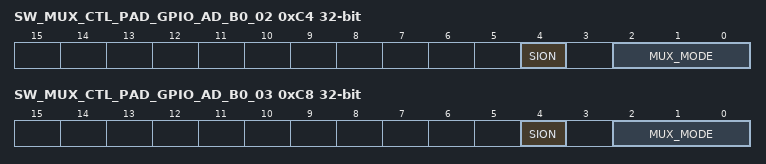
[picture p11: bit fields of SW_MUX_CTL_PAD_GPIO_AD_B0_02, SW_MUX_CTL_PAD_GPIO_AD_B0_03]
0xC4 SW_MUX_CTL_PAD_GPIO_AD_B0_02 — SW_MUX_CTL_PAD_GPIO_AD_B0_02 SW MUX Control Register
  [4] SION — Software Input On Field.
    0=DISABLED (Input Path is determined by functionality); 1=ENABLED (Force input path of pad GPIO_AD_B0_02)
  [2:0] MUX_MODE — MUX Mode Select Field.
    0=ALT0 (Select mux mode: ALT0 mux port: JTAG_MOD of instance: jtag_mux); 5=ALT5 (Select mux mode: ALT5 mux port: GPIO1_IO02 of instance: gpio1); 7=ALT7 (Select mux mode: ALT7 mux port: GPT1_CAPTURE1 of instance: gpt1)
0xC8 SW_MUX_CTL_PAD_GPIO_AD_B0_03 — SW_MUX_CTL_PAD_GPIO_AD_B0_03 SW MUX Control Register
  [4] SION — Software Input On Field.
    0=DISABLED (Input Path is determined by functionality); 1=ENABLED (Force input path of pad GPIO_AD_B0_03)
  [2:0] MUX_MODE — MUX Mode Select Field.
    0=ALT0 (Select mux mode: ALT0 mux port: JTAG_TDI of instance: jtag_mux); 1=ALT1 (Select mux mode: ALT1 mux port: USDHC2_CD_B of instance: usdhc2); 2=ALT2 (Select mux mode: ALT2 mux port: WDOG1_B of instance: wdog1); 3=ALT3 (Select mux mode: ALT3 mux port: SAI1_MCLK of instance: sai1); 4=ALT4 (Select mux mode: ALT4 mux port: USDHC1_WP of instance: usdhc1); 5=ALT5 (Select mux mode: ALT5 mux port: GPIO1_IO03 of instance: gpio1); 6=ALT6 (Select mux mode: ALT6 mux port: USB_OTG1_OC of instance: usb); 7=ALT7 (Select mux mode: ALT7 mux port: CCM_PMIC_RDY of instance: ccm)
